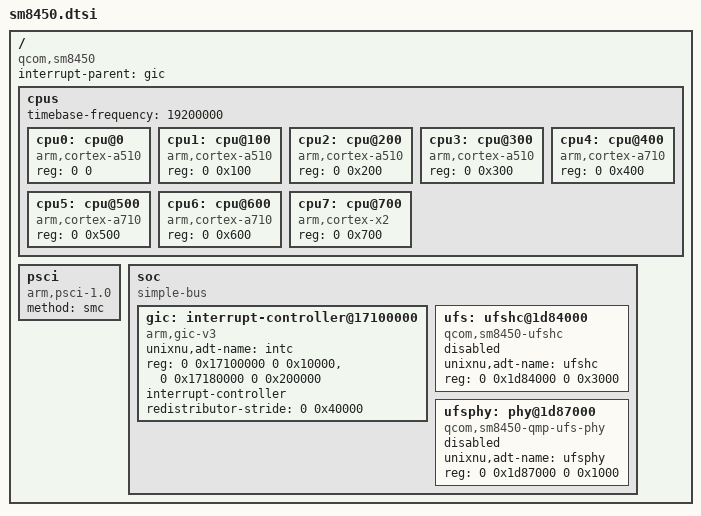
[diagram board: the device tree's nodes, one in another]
// SPDX-License-Identifier: BSD-3-Clause
// Resources from arch/arm64/boot/dts/qcom/sm8450.dtsi of linux-sm8450-mainline
// at 568f67832bd412ad47d8da3e77be9a835aff9986.
/ {
    compatible = "qcom,sm8450";
    #address-cells = <2>;
    #size-cells = <2>;
    interrupt-parent = <&gic>;

    cpus {
        #address-cells = <2>;
        #size-cells = <0>;
        timebase-frequency = <19200000>;
        cpu0: cpu@0 { device_type = "cpu"; compatible = "arm,cortex-a510"; reg = <0 0>; };
        cpu1: cpu@100 { device_type = "cpu"; compatible = "arm,cortex-a510"; reg = <0 0x100>; };
        cpu2: cpu@200 { device_type = "cpu"; compatible = "arm,cortex-a510"; reg = <0 0x200>; };
        cpu3: cpu@300 { device_type = "cpu"; compatible = "arm,cortex-a510"; reg = <0 0x300>; };
        cpu4: cpu@400 { device_type = "cpu"; compatible = "arm,cortex-a710"; reg = <0 0x400>; };
        cpu5: cpu@500 { device_type = "cpu"; compatible = "arm,cortex-a710"; reg = <0 0x500>; };
        cpu6: cpu@600 { device_type = "cpu"; compatible = "arm,cortex-a710"; reg = <0 0x600>; };
        cpu7: cpu@700 { device_type = "cpu"; compatible = "arm,cortex-x2"; reg = <0 0x700>; };
    };

    psci { compatible = "arm,psci-1.0"; method = "smc"; };

    soc {
        compatible = "simple-bus";
        #address-cells = <2>;
        #size-cells = <2>;
        ranges;

        gic: interrupt-controller@17100000 {
            compatible = "arm,gic-v3";
            unixnu,adt-name = "intc";
            reg = <0 0x17100000 0 0x10000>, <0 0x17180000 0 0x200000>;
            #interrupt-cells = <4>;
            #address-cells = <0>;
            interrupt-controller;
            redistributor-stride = <0 0x40000>;
        };

        ufs: ufshc@1d84000 {
            compatible = "qcom,sm8450-ufshc";
            unixnu,adt-name = "ufshc";
            reg = <0 0x1d84000 0 0x3000>;
            // No interrupts property: XNU maps a nub's interrupts through the parent's AAPL,phandle, which the ADT
            // generator does not emit (data abort in IODTGetICellCounts). Sm8475Ufs takes SPI 265 from its own facts.
            status = "disabled";
        };

        ufsphy: phy@1d87000 {
            compatible = "qcom,sm8450-qmp-ufs-phy";
            unixnu,adt-name = "ufsphy";
            reg = <0 0x1d87000 0 0x1000>;
            status = "disabled";
        };
    };
};
